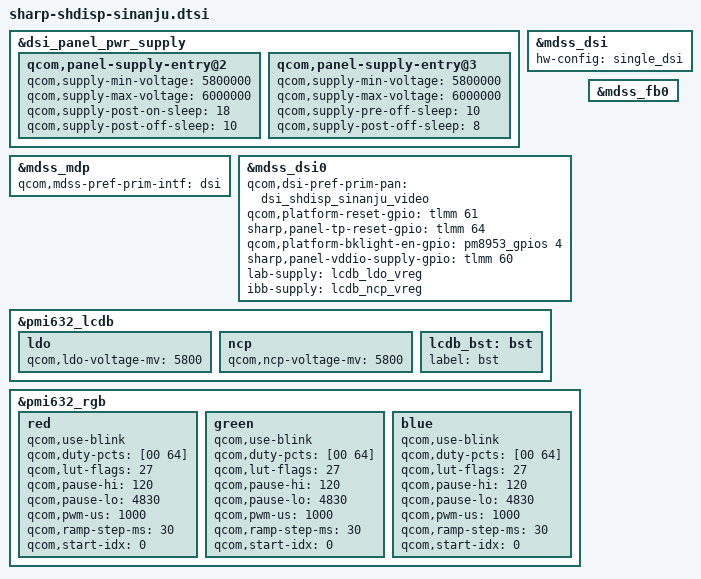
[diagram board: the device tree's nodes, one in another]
/* Copyright (c) 2017, The Linux Foundation. All rights reserved.
 *
 * This program is free software; you can redistribute it and/or modify
 * it under the terms of the GNU General Public License version 2 and
 * only version 2 as published by the Free Software Foundation.
 *
 * This program is distributed in the hope that it will be useful,
 * but WITHOUT ANY WARRANTY; without even the implied warranty of
 * MERCHANTABILITY or FITNESS FOR A PARTICULAR PURPOSE.  See the
 * GNU General Public License for more details.
 */
#include "sharp-shdisp-dsi-panel-sinanju-1080p-video.dtsi"

&dsi_panel_pwr_supply {
	qcom,panel-supply-entry@2 {
		qcom,supply-min-voltage = <5800000>;
		qcom,supply-max-voltage = <6000000>;
		qcom,supply-post-on-sleep = <18>;
		qcom,supply-post-off-sleep = <10>;
	};

	qcom,panel-supply-entry@3 {
		qcom,supply-min-voltage = <5800000>;
		qcom,supply-max-voltage = <6000000>;
		qcom,supply-pre-off-sleep = <10>;
		qcom,supply-post-off-sleep = <8>;
	};
};

&mdss_mdp {
	qcom,mdss-pref-prim-intf = "dsi";
};


&mdss_dsi {
	hw-config = "single_dsi";
};

&mdss_dsi0 {
	pinctrl-names = "mdss_default";
	pinctrl-0 = <&bklt_en_default>;
	qcom,dsi-pref-prim-pan = <&dsi_shdisp_sinanju_video>;

	/delete-property/ pinctrl-names;
	/delete-property/ pinctrl-0;
	/delete-property/ pinctrl-1;
	/delete-property/ qcom,platform-te-gpio;

	qcom,platform-reset-gpio = <&tlmm 61 0>;

	sharp,panel-tp-reset-gpio = <&tlmm 64 0>;

	qcom,platform-bklight-en-gpio = <&pm8953_gpios 4 0>;

	sharp,panel-vddio-supply-gpio = <&tlmm 60 0>;
	lab-supply = <&lcdb_ldo_vreg>;
	ibb-supply = <&lcdb_ncp_vreg>;
};

&pmi632_lcdb {
	ldo {
		qcom,ldo-voltage-mv = <5800>;
	};

	ncp {
		qcom,ncp-voltage-mv = <5800>;
	};

	lcdb_bst: bst {
		label = "bst";
	};
};

&pmi632_rgb {
	red {

		qcom,use-blink;
		qcom,duty-pcts = [00 64];
		qcom,lut-flags = <27>;
		qcom,pause-hi = <120>;
		qcom,pause-lo = <4830>;
		qcom,pwm-us = <1000>;
		qcom,ramp-step-ms = <30>;
		qcom,start-idx = <0>;
	};
	green {

		qcom,use-blink;
		qcom,duty-pcts = [00 64];
		qcom,lut-flags = <27>;
		qcom,pause-hi = <120>;
		qcom,pause-lo = <4830>;
		qcom,pwm-us = <1000>;
		qcom,ramp-step-ms = <30>;
		qcom,start-idx = <0>;
	};
	blue {

		qcom,use-blink;
		qcom,duty-pcts = [00 64];
		qcom,lut-flags = <27>;
		qcom,pause-hi = <120>;
		qcom,pause-lo = <4830>;
		qcom,pwm-us = <1000>;
		qcom,ramp-step-ms = <30>;
		qcom,start-idx = <0>;
	};
};

&mdss_fb0 {
	#cooling-cells = <2>;
};
